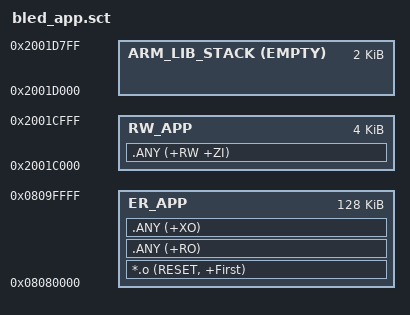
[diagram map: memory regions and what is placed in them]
; *************************************************************
; *** SVCrtOS 蓝灯应用(BLED_APP) 用户态分区 Scatter File     ***
; *** ROM 0x08080000，RAM 0x2001C000，与其他分区错开          ***
; *************************************************************

LR_APP 0x08080000 0x00020000  {        ; 应用 ROM 分区 128KB
  ER_APP 0x08080000 0x00020000  {
   *.o (RESET, +First)                 ; APPSTART 启动入口必须在最前
   .ANY (+RO)
   .ANY (+XO)
  }
  RW_APP 0x2001C000 0x00001000  {      ; 应用 RAM 4KB
   .ANY (+RW +ZI)
  }
  ARM_LIB_STACK 0x2001D800 EMPTY -0x800 {   ; 应用栈 2KB
  }
}
